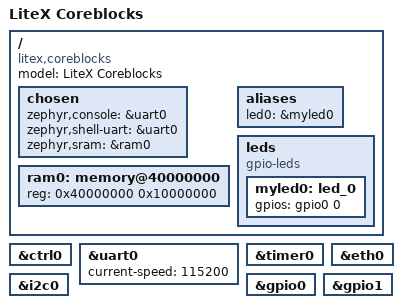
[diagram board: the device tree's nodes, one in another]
/*
 * Copyright (c) 2024 Piotr Wegrzyn (Kuznia Rdzeni)
 *
 * SPDX-License-Identifier: Apache-2.0
 */

/dts-v1/;

#include <litex/litex-coreblocks.dtsi>

#include <zephyr/dt-bindings/gpio/gpio.h>

/ {
	model = "LiteX Coreblocks";
	compatible = "litex,coreblocks";
	chosen {
		zephyr,console = &uart0;
		zephyr,shell-uart = &uart0;
		zephyr,sram = &ram0;
	};

	ram0: memory@40000000 {
		device_type = "memory";
		reg = <0x40000000 0x10000000>;
	};

	aliases { led0 = &myled0; };

	leds {
		compatible = "gpio-leds";
		myled0: led_0 {
			gpios = <&gpio0 0 GPIO_ACTIVE_HIGH>;
		};
	};
};

&ctrl0 {
	status = "okay";
};

&uart0 {
	status = "okay";
	current-speed = <115200>;
};

&timer0 {
	status = "okay";
};

&eth0 {
	status = "okay";
};

&i2c0 {
	status = "okay";
};

&gpio0 {
	status = "okay";
};

&gpio1 {
	status = "okay";
};

